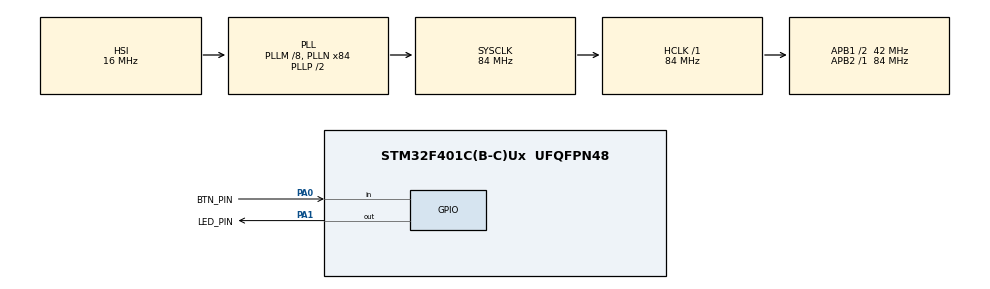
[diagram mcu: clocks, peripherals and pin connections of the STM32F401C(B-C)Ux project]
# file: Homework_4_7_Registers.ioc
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Mcu.Family=STM32F4
Mcu.Name=STM32F401C(B-C)Ux
Mcu.Package=UFQFPN48
NVIC.PriorityGroup=NVIC_PRIORITYGROUP_4
PA0-WKUP.GPIO_Label=BTN_PIN
PA0-WKUP.GPIO_PuPd=GPIO_PULLUP
PA0-WKUP.Signal=GPIO_Input
PA1.GPIO_Label=LED_PIN
PA1.Signal=GPIO_Output
PH0\ -\ OSC_IN.Mode=HSE-External-Oscillator
PH0\ -\ OSC_IN.Signal=RCC_OSC_IN
PH1\ -\ OSC_OUT.Mode=HSE-External-Oscillator
PH1\ -\ OSC_OUT.Signal=RCC_OSC_OUT
ProjectManager.HeapSize=0x200
ProjectManager.StackSize=0x400
ProjectManager.TargetToolchain=STM32CubeIDE
RCC.48MHZClocksFreq_Value=42000000
RCC.AHBFreq_Value=84000000
RCC.APB1CLKDivider=RCC_HCLK_DIV2
RCC.APB1Freq_Value=42000000
RCC.APB1TimFreq_Value=84000000
RCC.APB2Freq_Value=84000000
RCC.APB2TimFreq_Value=84000000
RCC.CortexFreq_Value=84000000
RCC.HCLKFreq_Value=84000000
RCC.HSE_VALUE=26000000
RCC.HSI_VALUE=16000000
RCC.LSE_VALUE=32768
RCC.PLLM=8
RCC.PLLN=84
RCC.SYSCLKFreq_VALUE=84000000
RCC.SYSCLKSource=RCC_SYSCLKSOURCE_PLLCLK
RCC.VCOOutputFreq_Value=168000000
board=custom

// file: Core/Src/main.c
/* USER CODE BEGIN Header */
/**
  ******************************************************************************
  * @file           : main.c
  * @brief          : Main program body
  ******************************************************************************
  * @attention
  *
  * Copyright (c) 2026 STMicroelectronics.
  * All rights reserved.
  *
  * This software is licensed under terms that can be found in the LICENSE file
  * in the root directory of this software component.
  * If no LICENSE file comes with this software, it is provided AS-IS.
  *
  ******************************************************************************
  */
/* USER CODE END Header */
#include "main.h"

void SystemClock_Config(void);
static void MX_GPIO_Init(void);

/* USER CODE BEGIN 0 */
void delay_ms(volatile uint32_t ms) {
    for (volatile uint32_t i = 0; i < (ms * 8400); i++) {
        __NOP();
    }
}
/* USER CODE END 0 */

int main(void)
{

  /* USER CODE BEGIN 1 */
	uint32_t periods[] = {100, 250, 500, 1000};
	  uint8_t current_index = 0;
	  uint32_t current_period = periods[current_index];

	  uint8_t last_button_state = 1;
  /* USER CODE END 1 */

  /* MCU Configuration--------------------------------------------------------*/

  /* Reset of all peripherals, Initializes the Flash interface and the Systick. */
  HAL_Init();

  /* Configure the system clock */
  SystemClock_Config();

  /* Initialize all configured peripherals */
  MX_GPIO_Init();

  /* Infinite loop */
  /* USER CODE BEGIN WHILE */
  while (1)
  {

	        GPIOA->BSRR = (1U << 1);
	        delay_ms(current_period / 2);

	        GPIOA->BSRR = (1U << (1 + 16));
	        delay_ms(current_period / 2);

	        uint8_t current_button_state = (GPIOA->IDR & (1U << 0)) ? 1 : 0;

	        if (last_button_state == 1 && current_button_state == 0)
	        {
	            delay_ms(20);

	            if ((GPIOA->IDR & (1U << 0)) == 0)
	            {
	               	                current_index = (current_index + 1) % 4;
	                current_period = periods[current_index];
	            }
	        }

	        last_button_state = current_button_state;
    /* USER CODE END WHILE */

  }
}

void SystemClock_Config(void)
{
  RCC_OscInitTypeDef RCC_OscInitStruct = {0};
  RCC_ClkInitTypeDef RCC_ClkInitStruct = {0};

  /** Configure the main internal regulator output voltage
  */
  __HAL_RCC_PWR_CLK_ENABLE();
  __HAL_PWR_VOLTAGESCALING_CONFIG(PWR_REGULATOR_VOLTAGE_SCALE2);

  /** Initializes the RCC Oscillators according to the specified parameters
  * in the RCC_OscInitTypeDef structure.
  */
  RCC_OscInitStruct.OscillatorType = RCC_OSCILLATORTYPE_HSI;
  RCC_OscInitStruct.HSIState = RCC_HSI_ON;
  RCC_OscInitStruct.HSICalibrationValue = RCC_HSICALIBRATION_DEFAULT;
  RCC_OscInitStruct.PLL.PLLState = RCC_PLL_ON;
  RCC_OscInitStruct.PLL.PLLSource = RCC_PLLSOURCE_HSI;
  RCC_OscInitStruct.PLL.PLLM = 8;
  RCC_OscInitStruct.PLL.PLLN = 84;
  RCC_OscInitStruct.PLL.PLLP = RCC_PLLP_DIV2;
  RCC_OscInitStruct.PLL.PLLQ = 4;
  if (HAL_RCC_OscConfig(&RCC_OscInitStruct) != HAL_OK)
  {
    Error_Handler();
  }

  /** Initializes the CPU, AHB and APB buses clocks
  */
  RCC_ClkInitStruct.ClockType = RCC_CLOCKTYPE_HCLK|RCC_CLOCKTYPE_SYSCLK
                              |RCC_CLOCKTYPE_PCLK1|RCC_CLOCKTYPE_PCLK2;
  RCC_ClkInitStruct.SYSCLKSource = RCC_SYSCLKSOURCE_PLLCLK;
  RCC_ClkInitStruct.AHBCLKDivider = RCC_SYSCLK_DIV1;
  RCC_ClkInitStruct.APB1CLKDivider = RCC_HCLK_DIV2;
  RCC_ClkInitStruct.APB2CLKDivider = RCC_HCLK_DIV1;

  if (HAL_RCC_ClockConfig(&RCC_ClkInitStruct, FLASH_LATENCY_2) != HAL_OK)
  {
    Error_Handler();
  }
}

static void MX_GPIO_Init(void)
{
  GPIO_InitTypeDef GPIO_InitStruct = {0};

  /* GPIO Ports Clock Enable */
  __HAL_RCC_GPIOH_CLK_ENABLE();
  __HAL_RCC_GPIOA_CLK_ENABLE();

  /*Configure GPIO pin Output Level */
  HAL_GPIO_WritePin(LED_PIN_GPIO_Port, LED_PIN_Pin, GPIO_PIN_RESET);

  /*Configure GPIO pin : BTN_PIN_Pin */
  GPIO_InitStruct.Pin = BTN_PIN_Pin;
  GPIO_InitStruct.Mode = GPIO_MODE_INPUT;
  GPIO_InitStruct.Pull = GPIO_PULLUP;
  HAL_GPIO_Init(BTN_PIN_GPIO_Port, &GPIO_InitStruct);

  /*Configure GPIO pin : LED_PIN_Pin */
  GPIO_InitStruct.Pin = LED_PIN_Pin;
  GPIO_InitStruct.Mode = GPIO_MODE_OUTPUT_PP;
  GPIO_InitStruct.Pull = GPIO_NOPULL;
  GPIO_InitStruct.Speed = GPIO_SPEED_FREQ_LOW;
  HAL_GPIO_Init(LED_PIN_GPIO_Port, &GPIO_InitStruct);

}

void Error_Handler(void)
{
  __disable_irq();
  while (1)
  {
  }
}
